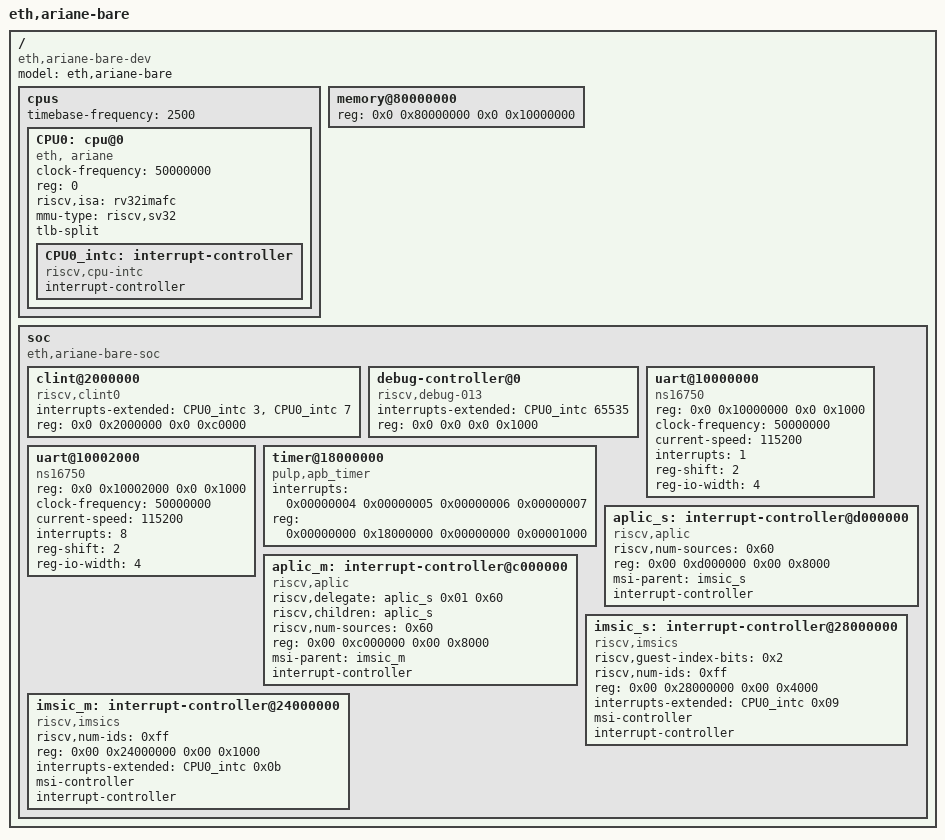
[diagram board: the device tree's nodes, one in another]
/dts-v1/;

/ {
  #address-cells = <2>;
  #size-cells = <2>;
  compatible = "eth,ariane-bare-dev";
  model = "eth,ariane-bare";
  cpus {
    #address-cells = <1>;
    #size-cells = <0>;
    timebase-frequency = <2500>; // 32.768 kHz
    CPU0: cpu@0 {
      clock-frequency = <50000000>; // 50 MHz
      device_type = "cpu";
      reg = <0>;
      status = "okay";
      compatible = "eth, ariane", "riscv";
      riscv,isa = "rv32imafc";
      mmu-type = "riscv,sv32";
      tlb-split;
      // HLIC - hart local interrupt controller
      CPU0_intc: interrupt-controller {
        #interrupt-cells = <1>;
        interrupt-controller;
        compatible = "riscv,cpu-intc";
      };
    };
  };
  memory@80000000 {
    device_type = "memory";
    reg = <0x0 0x80000000 0x0 0x10000000>;
  };
  soc {
    #address-cells = <2>;
    #size-cells = <2>;
    compatible = "eth,ariane-bare-soc", "simple-bus";
    ranges;
    clint@2000000 {
      compatible = "riscv,clint0";
      interrupts-extended = <&CPU0_intc 3 &CPU0_intc 7>;
      reg = <0x0 0x2000000 0x0 0xc0000>;
      reg-names = "control";
    };
    // PLIC needs to be disabeld for tandem verification
    // PLIC0: interrupt-controller@c000000 {
    //   #address-cells = <0>;
    //   #interrupt-cells = <1>;
    //   compatible = "sifive,plic-1.0.0", "riscv,plic0";
    //   interrupt-controller;
    //   interrupts-extended = <&CPU0_intc 11 &CPU0_intc 9>;
    //   reg = <0x0 0xc000000 0x0 0x4000000>;
    //   riscv,max-priority = <7>;
    //   riscv,ndev = <2>;
    // };
    debug-controller@0 {
      compatible = "riscv,debug-013";
      interrupts-extended = <&CPU0_intc 65535>;
      reg = <0x0 0x0 0x0 0x1000>;
      reg-names = "control";
    };
    uart@10000000 {
      compatible = "ns16750";
      reg = <0x0 0x10000000 0x0 0x1000>;
      clock-frequency = <50000000>;
      current-speed = <115200>;
      // interrupt-parent = <&PLIC0>;
      interrupts = <1>;
      reg-shift = <2>; // regs are spaced on 32 bit boundary
      reg-io-width = <4>; // only 32-bit access are supported
    };
    uart@10002000 {
      compatible = "ns16750";
      reg = <0x0 0x10002000 0x0 0x1000>;
      clock-frequency = <50000000>;
      current-speed = <115200>;
      // interrupt-parent = <&PLIC0>;
      interrupts = <8>;
      reg-shift = <2>; // regs are spaced on 32 bit boundary
      reg-io-width = <4>; // only 32-bit access are supported
    };  
    timer@18000000 {
      compatible = "pulp,apb_timer";
      interrupts = <0x00000004 0x00000005 0x00000006 0x00000007>;
      reg = <0x00000000 0x18000000 0x00000000 0x00001000>;
      // interrupt-parent = <&PLIC0>;
      reg-names = "control";
    };

    aplic_s: interrupt-controller@d000000 {
        riscv,num-sources = <0x60>;
        reg = <0x00 0xd000000 0x00 0x8000>;
        msi-parent = <&imsic_s>;
        interrupt-controller;
        #interrupt-cells = <0x02>;
        #address-cells = <0x00>;
        compatible = "riscv,aplic";
    };

    aplic_m: interrupt-controller@c000000 {
        riscv,delegate = <&aplic_s 0x01 0x60>;
        riscv,children = <&aplic_s>;
        riscv,num-sources = <0x60>;
        reg = <0x00 0xc000000 0x00 0x8000>;
        msi-parent = <&imsic_m>;
        interrupt-controller;
        #interrupt-cells = <0x02>;
        #address-cells = <0x00>;
        compatible = "riscv,aplic";
    };

    imsic_s: interrupt-controller@28000000 {
        riscv,guest-index-bits = <0x2>;
        riscv,num-ids = <0xff>;
        reg = <0x00 0x28000000 0x00 0x4000>;
        interrupts-extended = <&CPU0_intc 0x09>;
        msi-controller;
        interrupt-controller;
        #interrupt-cells = <0x00>;
        compatible = "riscv,imsics";
    };

    imsic_m: interrupt-controller@24000000 {
        riscv,num-ids = <0xff>;
        reg = <0x00 0x24000000 0x00 0x1000>;
        interrupts-extended = <&CPU0_intc 0x0b>;
        msi-controller;
        interrupt-controller;
        #interrupt-cells = <0x00>;
        compatible = "riscv,imsics";
    };

  };
};
